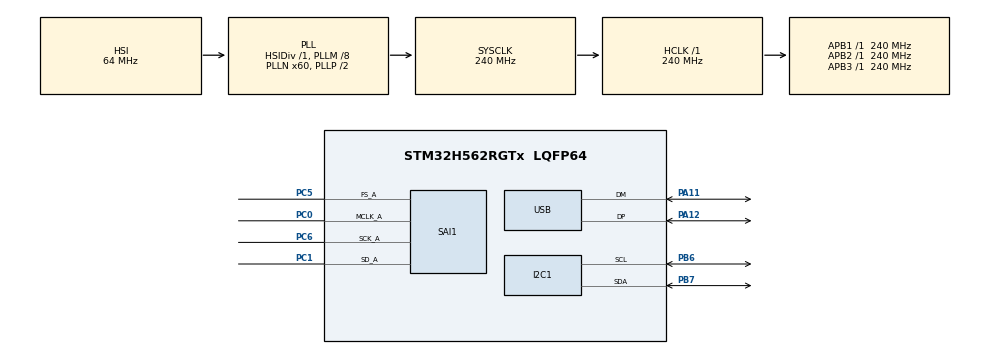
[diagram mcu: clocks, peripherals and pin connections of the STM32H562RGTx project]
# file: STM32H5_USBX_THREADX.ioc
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BOOTPATH.BootPathName=LEGACY
BOOTPATH.UserSelectedBootPath=LEGACY
CORTEX_M33_NS.userName=CORTEX_M33
GPDMA1.DESTDATAWIDTH_GPDMACH0=DMA_DEST_DATAWIDTH_HALFWORD
GPDMA1.DESTINC_GPDMACH0=DMA_DINC_INCREMENTED
GPDMA1.IPHANDLE_GPDMACH0-SIMPLEREQUEST_GPDMACH0=__NULL
GPDMA1.REQUEST_GPDMACH0=GPDMA1_REQUEST_SAI1_A
GPDMA1.SRCDATAWIDTH_GPDMACH0=DMA_SRC_DATAWIDTH_HALFWORD
I2C1.Timing=0x608087CA
Mcu.Family=STM32H5
Mcu.Name=STM32H562RGTx
Mcu.Package=LQFP64
NVIC.GPDMA1_Channel0_IRQn=true\:0\:0\:false\:false\:true\:true\:false\:true\:true
NVIC.PriorityGroup=NVIC_PRIORITYGROUP_4
NVIC.SAI1_IRQn=true\:0\:0\:false\:false\:true\:false\:true\:true\:true
NVIC.TIM6_IRQn=true\:15\:0\:false\:false\:true\:false\:false\:true\:true
NVIC.TimeBase=TIM6_IRQn
NVIC.TimeBaseIP=TIM6
NVIC.USB_DRD_FS_IRQn=true\:0\:0\:false\:false\:true\:false\:true\:true\:true
PA11.Mode=Device
PA11.Signal=USB_DM
PA12.Mode=Device
PA12.Signal=USB_DP
PA13(JTMS/SWDIO).Mode=Serial_Wire
PA13(JTMS/SWDIO).Signal=DEBUG_JTMS-SWDIO
PA14(JTCK/SWCLK).Mode=Serial_Wire
PA14(JTCK/SWCLK).Signal=DEBUG_JTCK-SWCLK
PB6.Mode=I2C
PB6.Signal=I2C1_SCL
PB7.Mode=I2C
PB7.Signal=I2C1_SDA
PC0.GPIO_Speed=GPIO_SPEED_FREQ_HIGH
PC0.Mode=SAI_A_MasterWithClock
PC0.Signal=SAI1_MCLK_A
PC1.GPIO_Speed=GPIO_SPEED_FREQ_HIGH
PC1.Mode=SAI_A_MasterWithClock
PC1.Signal=SAI1_SD_A
PC5.GPIO_Speed=GPIO_SPEED_FREQ_HIGH
PC5.Mode=SAI_A_MasterWithClock
PC5.Signal=SAI1_FS_A
PC6.GPIO_Speed=GPIO_SPEED_FREQ_HIGH
PC6.Mode=SAI_A_MasterWithClock
PC6.Signal=SAI1_SCK_A
ProjectManager.HeapSize=0x200
ProjectManager.StackSize=0x400
ProjectManager.TargetToolchain=EWARM V9.20
RCC.ADCFreq_Value=240000000
RCC.AHBFreq_Value=240000000
RCC.APB1Freq_Value=240000000
RCC.APB1TimFreq_Value=240000000
RCC.APB2Freq_Value=240000000
RCC.APB2TimFreq_Value=240000000
RCC.APB3Freq_Value=240000000
RCC.CSI_VALUE=4000000
RCC.CortexFreq_Value=240000000
RCC.EPOD_VALUE=64000000
RCC.HCLKFreq_Value=240000000
RCC.HSE_VALUE=25000000
RCC.HSI48_VALUE=48000000
RCC.HSIDiv=RCC_HSI_DIV1
RCC.HSI_VALUE=64000000
RCC.LSE_VALUE=32768
RCC.LSIRC_VALUE=32000
RCC.PLL2FRACN=4720
RCC.PLL2M=4
RCC.PLL2N=24
RCC.PLL2P=16
RCC.PLL2Source=RCC_PLL2_SOURCE_HSI
RCC.PLL3FRACN=5898
RCC.PLL3M=4
RCC.PLL3N=30
RCC.PLL3P=40
RCC.PLL3Source=RCC_PLL3_SOURCE_HSI
RCC.PLLM=8
RCC.PLLN=60
RCC.PLLSourceVirtual=RCC_PLL1_SOURCE_HSI
RCC.SAI1CLockSelection=RCC_SAI1CLKSOURCE_PLL3P
RCC.SYSCLKFreq_VALUE=240000000
RCC.SYSCLKSource=RCC_SYSCLKSOURCE_PLLCLK
RCC.USBFreq_Value=48000000
RCC.VCOOutputFreq_Value=480000000
SAI1.AudioFrequency-SAI_A_MasterWithClock=SAI_AUDIO_FREQUENCY_MCKDIV
SAI1.AudioMode-SAI_A_MasterWithClock=SAI_MODEMASTER_RX
SAI1.DataSize-SAI_A_MasterWithClock=SAI_DATASIZE_16
SAI1.ErrorAudioFreq-SAI_A_MasterWithClock=-75.0 %
SAI1.FIFOThreshold-SAI_A_MasterWithClock=SAI_FIFOTHRESHOLD_FULL
SAI1.FSOffset-SAI_A_MasterWithClock=SAI_FS_BEFOREFIRSTBIT
SAI1.FSPolarity-SAI_A_MasterWithClock=SAI_FS_ACTIVE_HIGH
SAI1.FrameLength-SAI_A_MasterWithClock=128
SAI1.Instance-SAI_A_MasterWithClock=SAI$Index_Block_A
SAI1.MckOutput=SAI_MCK_OUTPUT_ENABLE
SAI1.NoDivider-SAI_A_MasterWithClock=SAI_MASTERDIVIDER_ENABLE
SAI1.RealAudioFreq-SAI_A_MasterWithClock=47.999 KHz
SAI1.SlotActive-SAI_A_MasterWithClock=0x00000007
SAI1.SlotNumber-SAI_A_MasterWithClock=8
SAI1.VirtualMode-SAI_A_MasterWithClock=VM_MASTER
SAI1.VirtualSlotActive-SAI_A_MasterWithClock=SAI_SLOT_USERSETTING
SAI1.VirtualSlotActive0-SAI_A_MasterWithClock=true
SAI1.VirtualSlotActive1-SAI_A_MasterWithClock=true
SAI1.VirtualSlotActive2-SAI_A_MasterWithClock=true
THREADX.TX_APP_CREATION=1
THREADX.TX_APP_GENERATE_INIT_CODE=true
THREADX.TX_APP_MEM_POOL_SIZE=3*1024
USB.VirtualMode=Device_Only
USBX.BSP.number=1
USBX.Core_System=1
USBX.REG_USBX_DEVICE_CON_CK=0
USBX.USBD_CDCACM_EPINCMD_ADDR=2
USBX.USBD_CDCACM_EPIN_ADDR=1
USBX.USBX_DEVICE_SYS_SIZE=6*1024
USBX.UX_DEVICE_APP_MEM_POOL_SIZE=11*1024
USBX.UX_DEVICE_CDC_ACM=1
USBX.UX_DEVICE_CLASS_CDC_ACM_WRITE_AUTO_ZLP=1
USBX.UX_Device_Controller=1
USBX.UX_Device_CoreStack=1
USBX.UX_SLAVE_REQUEST_DATA_MAX_LENGTH=512
USBX0.BSP.STBoard=false
USBX0.BSP.api=Unknown
USBX0.BSP.instance=USB
USBX0.BSP.ip=USB
USBX0.BSP.mode=Device_Only
USBX0.BSP.name=USB_Device
USBX0.BSP.solution=USB
VP_BOOTPATH_VS_BOOTPATH.Mode=BP_Activate
VP_CORTEX_M33_NS_VS_Hclk.Mode=Hclk_Mode
VP_DCACHE1_VS_DCACHE.Mode=DCACHE_Activate
VP_GPDMA1_VS_GPDMACH0.Mode=SIMPLEREQUEST_GPDMACH0
VP_ICACHE_VS_ICACHE.Mode=DefaultMode
VP_MEMORYMAP_VS_MEMORYMAP.Mode=CurAppReg
VP_PWR_VS_LPOM.Mode=PowerOptimisation
VP_PWR_VS_SECSignals.Mode=Security/Privilege
VP_SYS_VS_tim6.Mode=TIM6
VP_THREADX_VS_RTOSJjThreadXJjCoreJjDefault.Mode=Core_Default
VP_USBX_Core_System.Mode=Core_System
VP_USBX_UX\ Device\ CDC\ ACM\ Class_FS.Mode=UX_Device_class_CDC_ACM_FS
VP_USBX_UX\ Device\ Controller_FS.Mode=UX_Device_Controller_FS
VP_USBX_UX\ Device\ CoreStack_FS.Mode=UX_Device_CoreStack_FS
board=custom

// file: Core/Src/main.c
/* USER CODE BEGIN Header */
/**
  ******************************************************************************
  * @file           : main.c
  * @brief          : Main program body
  ******************************************************************************
  * @attention
  *
  * Copyright (c) 2025 STMicroelectronics.
  * All rights reserved.
  *
  * This software is licensed under terms that can be found in the LICENSE file
  * in the root directory of this software component.
  * If no LICENSE file comes with this software, it is provided AS-IS.
  *
  ******************************************************************************
  */
/* USER CODE END Header */
#include "app_threadx.h"
#include "main.h"

/* USER CODE BEGIN Includes */
#include "ais25ba.h"
/* USER CODE END Includes */

DCACHE_HandleTypeDef hdcache1;

I2C_HandleTypeDef hi2c1;

SAI_HandleTypeDef hsai_BlockA1;
DMA_HandleTypeDef handle_GPDMA1_Channel0;

PCD_HandleTypeDef hpcd_USB_DRD_FS;

void SystemClock_Config(void);
static void MX_GPIO_Init(void);
static void MX_GPDMA1_Init(void);
static void MX_ICACHE_Init(void);
static void MX_DCACHE1_Init(void);
static void MX_SAI1_Init(void);
static void MX_I2C1_Init(void);
/* USER CODE BEGIN PFP */
void SAI2_MCLK_Enable(void);
/* USER CODE END PFP */

int main(void)
{

  /* MCU Configuration--------------------------------------------------------*/

  /* Reset of all peripherals, Initializes the Flash interface and the Systick. */
  HAL_Init();

  /* Configure the system clock */
  SystemClock_Config();

  /* Initialize all configured peripherals */
  MX_GPIO_Init();
  MX_GPDMA1_Init();
  MX_ICACHE_Init();
  MX_DCACHE1_Init();
  MX_SAI1_Init();
  MX_I2C1_Init();
  /* USER CODE BEGIN 2 */
  AIS25BA_Init();

  /* USER CODE END 2 */

  MX_ThreadX_Init();

  /* We should never get here as control is now taken by the scheduler */

  /* Infinite loop */
  while (1)
  {

  }
}

void SystemClock_Config(void)
{
  RCC_OscInitTypeDef RCC_OscInitStruct = {0};
  RCC_ClkInitTypeDef RCC_ClkInitStruct = {0};

  /** Configure the main internal regulator output voltage
  */
  __HAL_PWR_VOLTAGESCALING_CONFIG(PWR_REGULATOR_VOLTAGE_SCALE0);

  while(!__HAL_PWR_GET_FLAG(PWR_FLAG_VOSRDY)) {}

  /** Initializes the RCC Oscillators according to the specified parameters
  * in the RCC_OscInitTypeDef structure.
  */
  RCC_OscInitStruct.OscillatorType = RCC_OSCILLATORTYPE_HSI48|RCC_OSCILLATORTYPE_HSI;
  RCC_OscInitStruct.HSIState = RCC_HSI_ON;
  RCC_OscInitStruct.HSIDiv = RCC_HSI_DIV1;
  RCC_OscInitStruct.HSICalibrationValue = RCC_HSICALIBRATION_DEFAULT;
  RCC_OscInitStruct.HSI48State = RCC_HSI48_ON;
  RCC_OscInitStruct.PLL.PLLState = RCC_PLL_ON;
  RCC_OscInitStruct.PLL.PLLSource = RCC_PLL1_SOURCE_HSI;
  RCC_OscInitStruct.PLL.PLLM = 8;
  RCC_OscInitStruct.PLL.PLLN = 60;
  RCC_OscInitStruct.PLL.PLLP = 2;
  RCC_OscInitStruct.PLL.PLLQ = 2;
  RCC_OscInitStruct.PLL.PLLR = 2;
  RCC_OscInitStruct.PLL.PLLRGE = RCC_PLL1_VCIRANGE_3;
  RCC_OscInitStruct.PLL.PLLVCOSEL = RCC_PLL1_VCORANGE_WIDE;
  RCC_OscInitStruct.PLL.PLLFRACN = 0;
  if (HAL_RCC_OscConfig(&RCC_OscInitStruct) != HAL_OK)
  {
    Error_Handler();
  }

  /** Initializes the CPU, AHB and APB buses clocks
  */
  RCC_ClkInitStruct.ClockType = RCC_CLOCKTYPE_HCLK|RCC_CLOCKTYPE_SYSCLK
                              |RCC_CLOCKTYPE_PCLK1|RCC_CLOCKTYPE_PCLK2
                              |RCC_CLOCKTYPE_PCLK3;
  RCC_ClkInitStruct.SYSCLKSource = RCC_SYSCLKSOURCE_PLLCLK;
  RCC_ClkInitStruct.AHBCLKDivider = RCC_SYSCLK_DIV1;
  RCC_ClkInitStruct.APB1CLKDivider = RCC_HCLK_DIV1;
  RCC_ClkInitStruct.APB2CLKDivider = RCC_HCLK_DIV1;
  RCC_ClkInitStruct.APB3CLKDivider = RCC_HCLK_DIV1;

  if (HAL_RCC_ClockConfig(&RCC_ClkInitStruct, FLASH_LATENCY_5) != HAL_OK)
  {
    Error_Handler();
  }

  /** Configure the programming delay
  */
  __HAL_FLASH_SET_PROGRAM_DELAY(FLASH_PROGRAMMING_DELAY_2);
}

static void MX_DCACHE1_Init(void)
{

  hdcache1.Instance = DCACHE1;
  hdcache1.Init.ReadBurstType = DCACHE_READ_BURST_WRAP;
  if (HAL_DCACHE_Init(&hdcache1) != HAL_OK)
  {
    Error_Handler();
  }

}

static void MX_GPDMA1_Init(void)
{

  /* Peripheral clock enable */
  __HAL_RCC_GPDMA1_CLK_ENABLE();

  /* GPDMA1 interrupt Init */
    HAL_NVIC_SetPriority(GPDMA1_Channel0_IRQn, 0, 0);
    HAL_NVIC_EnableIRQ(GPDMA1_Channel0_IRQn);

}

static void MX_I2C1_Init(void)
{

  hi2c1.Instance = I2C1;
  hi2c1.Init.Timing = 0x608087CA;
  hi2c1.Init.OwnAddress1 = 0;
  hi2c1.Init.AddressingMode = I2C_ADDRESSINGMODE_7BIT;
  hi2c1.Init.DualAddressMode = I2C_DUALADDRESS_DISABLE;
  hi2c1.Init.OwnAddress2 = 0;
  hi2c1.Init.OwnAddress2Masks = I2C_OA2_NOMASK;
  hi2c1.Init.GeneralCallMode = I2C_GENERALCALL_DISABLE;
  hi2c1.Init.NoStretchMode = I2C_NOSTRETCH_DISABLE;
  if (HAL_I2C_Init(&hi2c1) != HAL_OK)
  {
    Error_Handler();
  }

  /** Configure Analogue filter
  */
  if (HAL_I2CEx_ConfigAnalogFilter(&hi2c1, I2C_ANALOGFILTER_ENABLE) != HAL_OK)
  {
    Error_Handler();
  }

  /** Configure Digital filter
  */
  if (HAL_I2CEx_ConfigDigitalFilter(&hi2c1, 0) != HAL_OK)
  {
    Error_Handler();
  }

}

static void MX_ICACHE_Init(void)
{

  /** Enable instruction cache (default 2-ways set associative cache)
  */
  if (HAL_ICACHE_Enable() != HAL_OK)
  {
    Error_Handler();
  }

}

static void MX_SAI1_Init(void)
{

  /* USER CODE BEGIN SAI1_Init 1 */
  hsai_BlockA1.Init.MckOverSampling = SAI_MCK_OVERSAMPLING_ENABLE;
  /* USER CODE END SAI1_Init 1 */
  hsai_BlockA1.Instance = SAI1_Block_A;
  hsai_BlockA1.Init.Protocol = SAI_FREE_PROTOCOL;
  hsai_BlockA1.Init.AudioMode = SAI_MODEMASTER_RX;
  hsai_BlockA1.Init.DataSize = SAI_DATASIZE_16;
  hsai_BlockA1.Init.FirstBit = SAI_FIRSTBIT_MSB;
  hsai_BlockA1.Init.ClockStrobing = SAI_CLOCKSTROBING_FALLINGEDGE;
  hsai_BlockA1.Init.Synchro = SAI_ASYNCHRONOUS;
  hsai_BlockA1.Init.OutputDrive = SAI_OUTPUTDRIVE_DISABLE;
  hsai_BlockA1.Init.NoDivider = SAI_MASTERDIVIDER_ENABLE;
  hsai_BlockA1.Init.FIFOThreshold = SAI_FIFOTHRESHOLD_FULL;
  hsai_BlockA1.Init.AudioFrequency = SAI_AUDIO_FREQUENCY_MCKDIV;
  hsai_BlockA1.Init.Mckdiv = 0;
  hsai_BlockA1.Init.SynchroExt = SAI_SYNCEXT_DISABLE;
  hsai_BlockA1.Init.MckOutput = SAI_MCK_OUTPUT_ENABLE;
  hsai_BlockA1.Init.MonoStereoMode = SAI_STEREOMODE;
  hsai_BlockA1.Init.CompandingMode = SAI_NOCOMPANDING;
  hsai_BlockA1.Init.PdmInit.Activation = DISABLE;
  hsai_BlockA1.Init.PdmInit.MicPairsNbr = 1;
  hsai_BlockA1.Init.PdmInit.ClockEnable = SAI_PDM_CLOCK1_ENABLE;
  hsai_BlockA1.FrameInit.FrameLength = 128;
  hsai_BlockA1.FrameInit.ActiveFrameLength = 1;
  hsai_BlockA1.FrameInit.FSDefinition = SAI_FS_STARTFRAME;
  hsai_BlockA1.FrameInit.FSPolarity = SAI_FS_ACTIVE_HIGH;
  hsai_BlockA1.FrameInit.FSOffset = SAI_FS_BEFOREFIRSTBIT;
  hsai_BlockA1.SlotInit.FirstBitOffset = 0;
  hsai_BlockA1.SlotInit.SlotSize = SAI_SLOTSIZE_DATASIZE;
  hsai_BlockA1.SlotInit.SlotNumber = 8;
  hsai_BlockA1.SlotInit.SlotActive = 0x00000007;
  if (HAL_SAI_Init(&hsai_BlockA1) != HAL_OK)
  {
    Error_Handler();
  }

}

void MX_USB_PCD_Init(void)
{

  hpcd_USB_DRD_FS.Instance = USB_DRD_FS;
  hpcd_USB_DRD_FS.Init.dev_endpoints = 8;
  hpcd_USB_DRD_FS.Init.speed = USBD_FS_SPEED;
  hpcd_USB_DRD_FS.Init.phy_itface = PCD_PHY_EMBEDDED;
  hpcd_USB_DRD_FS.Init.Sof_enable = DISABLE;
  hpcd_USB_DRD_FS.Init.low_power_enable = DISABLE;
  hpcd_USB_DRD_FS.Init.lpm_enable = DISABLE;
  hpcd_USB_DRD_FS.Init.battery_charging_enable = DISABLE;
  hpcd_USB_DRD_FS.Init.vbus_sensing_enable = DISABLE;
  hpcd_USB_DRD_FS.Init.bulk_doublebuffer_enable = DISABLE;
  hpcd_USB_DRD_FS.Init.iso_singlebuffer_enable = DISABLE;
  if (HAL_PCD_Init(&hpcd_USB_DRD_FS) != HAL_OK)
  {
    Error_Handler();
  }

}

static void MX_GPIO_Init(void)
{

  /* GPIO Ports Clock Enable */
  __HAL_RCC_GPIOC_CLK_ENABLE();
  __HAL_RCC_GPIOA_CLK_ENABLE();
  __HAL_RCC_GPIOB_CLK_ENABLE();

}

void HAL_TIM_PeriodElapsedCallback(TIM_HandleTypeDef *htim)
{
  if (htim->Instance == TIM6)
  {
    HAL_IncTick();
  }
}

void Error_Handler(void)
{
  __disable_irq();
  while (1)
  {
  }
}
